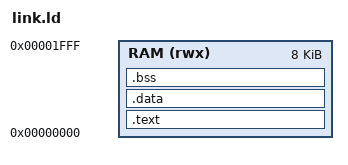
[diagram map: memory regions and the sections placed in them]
/* Linker Script for Hazard5 RISC-V Multi-Cart Firmware */
OUTPUT_ARCH("riscv")
ENTRY(_start)

MEMORY
{
    RAM (rwx) : ORIGIN = 0x00000000, LENGTH = 8K
}

SECTIONS
{
    .text : {
        *(.text.start)
        *(.text*)
        *(.rodata*)
    } > RAM

    .data : {
        *(.data*)
        *(.sdata*)
    } > RAM

    .bss : {
        __bss_start = .;
        *(.bss*)
        *(.sbss*)
        __bss_end = .;
    } > RAM

    _stack_top = ORIGIN(RAM) + LENGTH(RAM);
}
